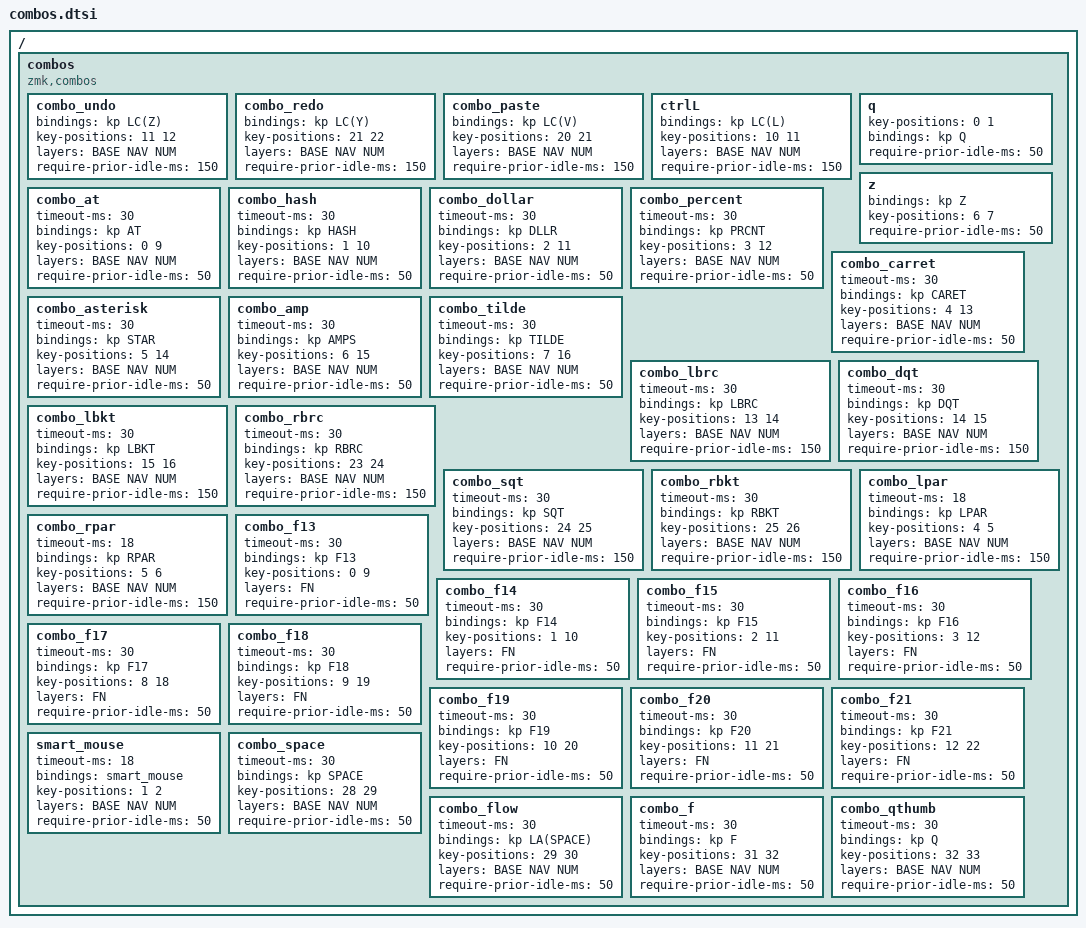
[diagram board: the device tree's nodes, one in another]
/ {
    combos {
        compatible = "zmk,combos";
        // Clipboard
        combo_undo {
            bindings = <&kp LC(Z)>;
            key-positions = <11 12>;
            layers = <BASE NAV NUM>; 
            require-prior-idle-ms = <150>;
        };
        combo_redo {
            bindings = <&kp LC(Y)>;
            key-positions = <21 22>;
            layers = <BASE NAV NUM>; 
            require-prior-idle-ms = <150>;
        };
        combo_paste {
            bindings = <&kp LC(V)>;
            key-positions = <20 21>;
            layers = <BASE NAV NUM>; 
            require-prior-idle-ms = <150>;
        };
        ctrlL {
            bindings = <&kp LC(L)>;
            key-positions = <10 11>;
            layers = <BASE NAV NUM>; 
            require-prior-idle-ms = <150>;
        };

        // Letters
        q {
            key-positions = <0 1>;
            bindings = <&kp Q>;
            require-prior-idle-ms = <50>;
        };

        z {
            bindings = <&kp Z>;
            key-positions = <6 7>;
            require-prior-idle-ms = <50>;
        };


        // Vertical Top Symbols Left
        combo_at {
            timeout-ms = <30>;
            bindings = <&kp AT>;
            key-positions = <0 9>;
            layers = <BASE NAV NUM>; 
            require-prior-idle-ms = <50>;
        };
        combo_hash {
            timeout-ms = <30>;
            bindings = <&kp HASH >;
            key-positions = <1 10>;
            layers = <BASE NAV NUM>; 
            require-prior-idle-ms = <50>;
        };
        combo_dollar {
            timeout-ms = <30>;
            bindings = <&kp DLLR >;
            key-positions = <2 11>;
            layers = <BASE NAV NUM>; 
            require-prior-idle-ms = <50>;
        };
        combo_percent {
            timeout-ms = <30>;
            bindings = <&kp PRCNT >;
            key-positions = <3 12>;
            layers = <BASE NAV NUM>; 
            require-prior-idle-ms = <50>;
        }; 
        combo_carret {
            timeout-ms = <30>;
            bindings = <&kp CARET >;
            key-positions = <4 13>;
            layers = <BASE NAV NUM>; 
            require-prior-idle-ms = <50>;
        };
        combo_asterisk {
            timeout-ms = <30>;
            bindings = <&kp STAR >;
            key-positions = <5 14>;
            layers = <BASE NAV NUM>; 
            require-prior-idle-ms = <50>;
        };
        combo_amp {
            timeout-ms = <30>;
            bindings = <&kp AMPS >;
            key-positions = <6 15>;
            layers = <BASE NAV NUM>; 
            require-prior-idle-ms = <50>;
        };
        combo_tilde {
            timeout-ms = <30>;
            bindings = <&kp TILDE >;
            key-positions = <7 16>;
            layers = <BASE NAV NUM>; 
            require-prior-idle-ms = <50>;
        };

        // Horizontal Middle
        combo_lbrc {
            timeout-ms = <30>;
            bindings = <&kp LBRC >;
            key-positions = <13 14>;
            layers = <BASE NAV NUM>; 
            require-prior-idle-ms = <150>;
        };
        combo_dqt {
            timeout-ms = <30>;
            bindings = <&kp DQT>;
            key-positions = <14 15>;
            layers = <BASE NAV NUM>; 
            require-prior-idle-ms = <150>;
        };
        combo_lbkt {
            timeout-ms = <30>;
            bindings = <&kp LBKT >;
            key-positions = <15 16>;
            layers = <BASE NAV NUM>; 
            require-prior-idle-ms = <150>;
        };
        combo_rbrc {
            timeout-ms = <30>;
            bindings = <&kp RBRC >;
            key-positions = <23 24>;
            layers = <BASE NAV NUM>; 
            require-prior-idle-ms = <150>;
        };
        combo_sqt {
            timeout-ms = <30>;
            bindings = <&kp SQT>;
            key-positions = <24 25>;
            layers = <BASE NAV NUM>; 
            require-prior-idle-ms = <150>;
        };
        combo_rbkt {
            timeout-ms = <30>;
            bindings = <&kp RBKT >;
            key-positions = <25 26>;
            layers = <BASE NAV NUM>; 
            require-prior-idle-ms = <150>;
        };
        combo_lpar {
            timeout-ms = <18>;
            bindings = <&kp LPAR >;
            key-positions = <4 5>;
            layers = <BASE NAV NUM>; 
            require-prior-idle-ms = <150>;
        };
        combo_rpar {
            timeout-ms = <18>;
            bindings = <&kp RPAR >;
            key-positions = <5 6>;
            layers = <BASE NAV NUM>; 
            require-prior-idle-ms = <150>;
        };
        
        // Vertical FN keys
        combo_f13 {
            timeout-ms = <30>;
            bindings = <&kp F13>;
            key-positions = <0 9>;
            layers = <FN>; 
            require-prior-idle-ms = <50>;
        };
        combo_f14 {
            timeout-ms = <30>;
            bindings = <&kp F14>;
            key-positions = <1 10>;
            layers = <FN>; 
            require-prior-idle-ms = <50>;
        };
        combo_f15 {
            timeout-ms = <30>;
            bindings = <&kp F15>;
            key-positions = <2 11>;
            layers = <FN>; 
            require-prior-idle-ms = <50>;
        };
        combo_f16 {
            timeout-ms = <30>;
            bindings = <&kp F16>;
            key-positions = <3 12>;
            layers = <FN>; 
            require-prior-idle-ms = <50>;
        };
        combo_f17 {
            timeout-ms = <30>;
            bindings = <&kp F17>;
            key-positions = <8 18>;
            layers = <FN>; 
            require-prior-idle-ms = <50>;
        };
        combo_f18 {
            timeout-ms = <30>;
            bindings = <&kp F18>;
            key-positions = <9 19>;
            layers = <FN>; 
            require-prior-idle-ms = <50>;
        };
        combo_f19 {
            timeout-ms = <30>;
            bindings = <&kp F19>;
            key-positions = <10 20>;
            layers = <FN>; 
            require-prior-idle-ms = <50>;
        };
        combo_f20 {
            timeout-ms = <30>;
            bindings = <&kp F20>;
            key-positions = <11 21>;
            layers = <FN>; 
            require-prior-idle-ms = <50>;
        };
        combo_f21 {
            timeout-ms = <30>;
            bindings = <&kp F21>;
            key-positions = <12 22>;
            layers = <FN>; 
            require-prior-idle-ms = <50>;
        };
        // Mouse
        smart_mouse {
            timeout-ms = <18>;
            bindings = <&smart_mouse>;
            key-positions = <1 2>;
            layers = <BASE NAV NUM>; 
            require-prior-idle-ms = <50>;
        };
        // Thumb Left
        combo_space {
            timeout-ms = <30>;
            bindings = <&kp SPACE>;
            key-positions = <28 29>;
            layers = <BASE NAV NUM>; 
            require-prior-idle-ms = <50>;
        };
        combo_flow {
            timeout-ms = <30>;
            bindings = <&kp LA(SPACE)>;
            key-positions = <29 30>;
            layers = <BASE NAV NUM>; 
            require-prior-idle-ms = <50>;
        };

        // Thumb Right
        combo_f {
            timeout-ms = <30>;
            bindings = <&kp F>;
            key-positions = <31 32>;
            layers = <BASE NAV NUM>; 
            require-prior-idle-ms = <50>;
        };
        combo_qthumb {
            timeout-ms = <30>;
            bindings = <&kp Q>;
            key-positions = <32 33>;
            layers = <BASE NAV NUM>; 
            require-prior-idle-ms = <50>;
        };
    };
};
